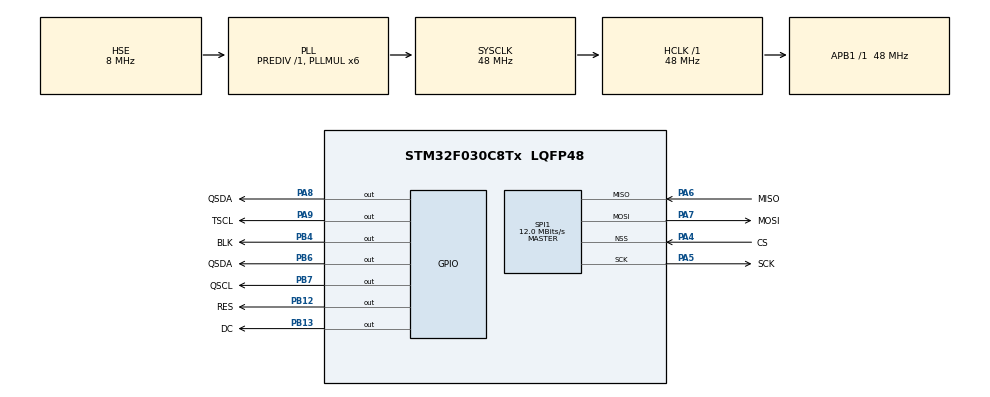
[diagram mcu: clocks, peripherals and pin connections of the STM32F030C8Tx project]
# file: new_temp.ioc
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Mcu.Family=STM32F0
Mcu.Name=STM32F030C8Tx
Mcu.Package=LQFP48
PA0.GPIO_Label=KEY
PA0.Mode=SYS_WakeUp0
PA0.Signal=SYS_WKUP1
PA13.Mode=Serial_Wire
PA13.Signal=SYS_SWDIO
PA14.Mode=Serial_Wire
PA14.Signal=SYS_SWCLK
PA4.GPIO_Label=CS
PA4.Mode=NSS_Signal_Hard_Input
PA4.Signal=SPI1_NSS
PA5.GPIO_Label=SCK
PA5.Mode=Full_Duplex_Master
PA5.Signal=SPI1_SCK
PA6.GPIO_Label=MISO
PA6.Mode=Full_Duplex_Master
PA6.Signal=SPI1_MISO
PA7.GPIO_Label=MOSI
PA7.Mode=Full_Duplex_Master
PA7.Signal=SPI1_MOSI
PA8.GPIO_Label=QSDA
PA8.GPIO_ModeDefaultOutputPP=GPIO_MODE_OUTPUT_OD
PA8.GPIO_PuPd=GPIO_NOPULL
PA8.PinState=GPIO_PIN_SET
PA8.Signal=GPIO_Output
PA9.GPIO_Label=TSCL
PA9.GPIO_ModeDefaultOutputPP=GPIO_MODE_OUTPUT_OD
PA9.GPIO_PuPd=GPIO_NOPULL
PA9.PinState=GPIO_PIN_SET
PA9.Signal=GPIO_Output
PB12.GPIO_Label=RES
PB12.GPIO_ModeDefaultOutputPP=GPIO_MODE_OUTPUT_OD
PB12.GPIO_PuPd=GPIO_NOPULL
PB12.GPIO_Speed=GPIO_SPEED_FREQ_HIGH
PB12.Signal=GPIO_Output
PB13.GPIO_Label=DC
PB13.GPIO_ModeDefaultOutputPP=GPIO_MODE_OUTPUT_OD
PB13.GPIO_PuPd=GPIO_NOPULL
PB13.GPIO_Speed=GPIO_SPEED_FREQ_HIGH
PB13.Signal=GPIO_Output
PB4.GPIO_Label=BLK
PB4.GPIO_ModeDefaultOutputPP=GPIO_MODE_OUTPUT_OD
PB4.GPIO_PuPd=GPIO_NOPULL
PB4.GPIO_Speed=GPIO_SPEED_FREQ_HIGH
PB4.PinState=GPIO_PIN_SET
PB4.Signal=GPIO_Output
PB6.GPIO_Label=QSDA
PB6.PinState=GPIO_PIN_SET
PB6.Signal=GPIO_Output
PB7.GPIO_Label=QSCL
PB7.GPIO_ModeDefaultOutputPP=GPIO_MODE_OUTPUT_OD
PB7.GPIO_PuPd=GPIO_NOPULL
PB7.GPIO_Speed=GPIO_SPEED_FREQ_LOW
PB7.PinState=GPIO_PIN_SET
PB7.Signal=GPIO_Output
PF0-OSC_IN.Mode=HSE-External-Oscillator
PF0-OSC_IN.Signal=RCC_OSC_IN
PF1-OSC_OUT.Mode=HSE-External-Oscillator
PF1-OSC_OUT.Signal=RCC_OSC_OUT
ProjectManager.HeapSize=0x200
ProjectManager.StackSize=0x400
ProjectManager.TargetToolchain=STM32CubeIDE
RCC.AHBFreq_Value=48000000
RCC.APB1Freq_Value=48000000
RCC.APB1TimFreq_Value=48000000
RCC.HCLKFreq_Value=48000000
RCC.PLLMUL=RCC_PLL_MUL6
RCC.PLLSourceVirtual=RCC_PLLSOURCE_HSE
RCC.SYSCLKFreq_VALUE=48000000
RCC.SYSCLKSource=RCC_SYSCLKSOURCE_PLLCLK
SPI1.BaudRatePrescaler=SPI_BAUDRATEPRESCALER_4
SPI1.CRCCalculation=SPI_CRCCALCULATION_DISABLE
SPI1.CalculateBaudRate=12.0 MBits/s
SPI1.DataSize=SPI_DATASIZE_8BIT
SPI1.Direction=SPI_DIRECTION_2LINES
SPI1.Mode=SPI_MODE_MASTER
SPI1.VirtualNSS=VM_NSSHARD
SPI1.VirtualType=VM_MASTER
TIM1.Prescaler=48
VP_TIM1_VS_ClockSourceINT.Mode=Internal
board=custom

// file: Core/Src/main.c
/* USER CODE BEGIN Header */
/**
  ******************************************************************************
  * @file           : main.c
  * @brief          : Main program body
  ******************************************************************************
  * @attention
  *
  * Copyright (c) 2022 STMicroelectronics.
  * All rights reserved.
  *
  * This software is licensed under terms that can be found in the LICENSE file
  * in the root directory of this software component.
  * If no LICENSE file comes with this software, it is provided AS-IS.
  *
  ******************************************************************************
  */
/* USER CODE END Header */
#include "main.h"
#include "lcd_init.h"
#include "lcd.h"

SPI_HandleTypeDef hspi1;

void SystemClock_Config(void);

static void MX_GPIO_Init(void);

static void MX_SPI1_Init(void);

static void MX_TIM1_Init(void);

int main(void) {

    /* MCU Configuration--------------------------------------------------------*/

    /* Reset of all peripherals, Initializes the Flash interface and the Systick. */
    HAL_Init();

    /* Configure the system clock */
    SystemClock_Config();

    /* USER CODE BEGIN SysInit */
    __HAL_RCC_GPIOA_CLK_ENABLE();
    __HAL_RCC_GPIOB_CLK_ENABLE();
    /* USER CODE END SysInit */

    /* Initialize all configured peripherals */
    MX_GPIO_Init();
    MX_SPI1_Init();
    MX_TIM1_Init();
    /* USER CODE BEGIN 2 */
    LCD_GPIO_Init();
    /* USER CODE END 2 */

    /* Infinite loop */
    while (1) {
        LCD_ShowChinese(0,0,"中景园电子",RED,WHITE,24,0);
        LCD_ShowString(24,30,"LCD_W:",RED,WHITE,16,0);
        LCD_ShowIntNum(72,30,LCD_W,3,RED,WHITE,16);
        LCD_ShowString(24,50,"LCD_H:",RED,WHITE,16,0);
        LCD_ShowIntNum(72,50,LCD_H,3,RED,WHITE,16);
//        LCD_ShowFloatNum1(20,80,t,4,RED,WHITE,16);
    }
}

void SystemClock_Config(void) {
    RCC_OscInitTypeDef RCC_OscInitStruct = {0};
    RCC_ClkInitTypeDef RCC_ClkInitStruct = {0};

    /** Initializes the RCC Oscillators according to the specified parameters
    * in the RCC_OscInitTypeDef structure.
    */
    RCC_OscInitStruct.OscillatorType = RCC_OSCILLATORTYPE_HSE;
    RCC_OscInitStruct.HSEState = RCC_HSE_ON;
    RCC_OscInitStruct.PLL.PLLState = RCC_PLL_ON;
    RCC_OscInitStruct.PLL.PLLSource = RCC_PLLSOURCE_HSE;
    RCC_OscInitStruct.PLL.PLLMUL = RCC_PLL_MUL6;
    RCC_OscInitStruct.PLL.PREDIV = RCC_PREDIV_DIV1;
    if (HAL_RCC_OscConfig(&RCC_OscInitStruct) != HAL_OK) {
        Error_Handler();
    }

    /** Initializes the CPU, AHB and APB buses clocks
    */
    RCC_ClkInitStruct.ClockType = RCC_CLOCKTYPE_HCLK | RCC_CLOCKTYPE_SYSCLK
                                  | RCC_CLOCKTYPE_PCLK1;
    RCC_ClkInitStruct.SYSCLKSource = RCC_SYSCLKSOURCE_PLLCLK;
    RCC_ClkInitStruct.AHBCLKDivider = RCC_SYSCLK_DIV1;
    RCC_ClkInitStruct.APB1CLKDivider = RCC_HCLK_DIV1;

    if (HAL_RCC_ClockConfig(&RCC_ClkInitStruct, FLASH_LATENCY_1) != HAL_OK) {
        Error_Handler();
    }
}

static void MX_SPI1_Init(void) {

    /* SPI1 parameter configuration*/
    hspi1.Instance = SPI1;
    hspi1.Init.Mode = SPI_MODE_MASTER;
    hspi1.Init.Direction = SPI_DIRECTION_2LINES;
    hspi1.Init.DataSize = SPI_DATASIZE_8BIT;
    hspi1.Init.CLKPolarity = SPI_POLARITY_LOW;
    hspi1.Init.CLKPhase = SPI_PHASE_1EDGE;
    hspi1.Init.NSS = SPI_NSS_HARD_INPUT;
    hspi1.Init.BaudRatePrescaler = SPI_BAUDRATEPRESCALER_4;
    hspi1.Init.FirstBit = SPI_FIRSTBIT_MSB;
    hspi1.Init.TIMode = SPI_TIMODE_DISABLE;
    hspi1.Init.CRCCalculation = SPI_CRCCALCULATION_DISABLE;
    hspi1.Init.CRCPolynomial = 7;
    hspi1.Init.CRCLength = SPI_CRC_LENGTH_DATASIZE;
    hspi1.Init.NSSPMode = SPI_NSS_PULSE_ENABLE;
    if (HAL_SPI_Init(&hspi1) != HAL_OK) {
        Error_Handler();
    }

}

static void MX_TIM1_Init(void) {

    TIM_ClockConfigTypeDef sClockSourceConfig = {0};
    TIM_MasterConfigTypeDef sMasterConfig = {0};

    htim1.Instance = TIM1;
    htim1.Init.Prescaler = 48;
    htim1.Init.CounterMode = TIM_COUNTERMODE_UP;
    htim1.Init.Period = 65535;
    htim1.Init.ClockDivision = TIM_CLOCKDIVISION_DIV1;
    htim1.Init.RepetitionCounter = 0;
    htim1.Init.AutoReloadPreload = TIM_AUTORELOAD_PRELOAD_DISABLE;
    if (HAL_TIM_Base_Init(&htim1) != HAL_OK) {
        Error_Handler();
    }
    sClockSourceConfig.ClockSource = TIM_CLOCKSOURCE_INTERNAL;
    if (HAL_TIM_ConfigClockSource(&htim1, &sClockSourceConfig) != HAL_OK) {
        Error_Handler();
    }
    sMasterConfig.MasterOutputTrigger = TIM_TRGO_RESET;
    sMasterConfig.MasterSlaveMode = TIM_MASTERSLAVEMODE_DISABLE;
    if (HAL_TIMEx_MasterConfigSynchronization(&htim1, &sMasterConfig) != HAL_OK) {
        Error_Handler();
    }

}

static void MX_GPIO_Init(void) {
    GPIO_InitTypeDef GPIO_InitStruct = {0};

    /* GPIO Ports Clock Enable */
    __HAL_RCC_GPIOC_CLK_ENABLE();
    __HAL_RCC_GPIOF_CLK_ENABLE();
    __HAL_RCC_GPIOA_CLK_ENABLE();
    __HAL_RCC_GPIOB_CLK_ENABLE();

    /*Configure GPIO pin Output Level */
//  HAL_GPIO_WritePin(GPIOB, RES_Pin|DC_Pin, GPIO_PIN_RESET);

    /*Configure GPIO pin Output Level */
//  HAL_GPIO_WritePin(GPIOA, QSDA_Pin|TSCL_Pin, GPIO_PIN_SET);

    /*Configure GPIO pin Output Level */
//  HAL_GPIO_WritePin(GPIOB, BLK_Pin|QSDAB6_Pin|QSCL_Pin, GPIO_PIN_SET);

    /*Configure GPIO pins : PC13 PC14 PC15 */
    GPIO_InitStruct.Pin = GPIO_PIN_13 | GPIO_PIN_14 | GPIO_PIN_15;
    GPIO_InitStruct.Mode = GPIO_MODE_ANALOG;
    GPIO_InitStruct.Pull = GPIO_NOPULL;
    HAL_GPIO_Init(GPIOC, &GPIO_InitStruct);

    /*Configure GPIO pins : PA1 PA2 PA3 PA10
                             PA11 PA12 PA15 */
    GPIO_InitStruct.Pin = GPIO_PIN_1 | GPIO_PIN_2 | GPIO_PIN_3 | GPIO_PIN_10
                          | GPIO_PIN_11 | GPIO_PIN_12 | GPIO_PIN_15;
    GPIO_InitStruct.Mode = GPIO_MODE_ANALOG;
    GPIO_InitStruct.Pull = GPIO_NOPULL;
    HAL_GPIO_Init(GPIOA, &GPIO_InitStruct);

    /*Configure GPIO pins : PB0 PB1 PB2 PB10
                             PB11 PB14 PB15 PB3
                             PB5 PB8 PB9 */
    GPIO_InitStruct.Pin = GPIO_PIN_0 | GPIO_PIN_1 | GPIO_PIN_2 | GPIO_PIN_10
                          | GPIO_PIN_11 | GPIO_PIN_14 | GPIO_PIN_15 | GPIO_PIN_3
                          | GPIO_PIN_5 | GPIO_PIN_8 | GPIO_PIN_9;
    GPIO_InitStruct.Mode = GPIO_MODE_ANALOG;
    GPIO_InitStruct.Pull = GPIO_NOPULL;
    HAL_GPIO_Init(GPIOB, &GPIO_InitStruct);

    /*Configure GPIO pins : RES_Pin DC_Pin BLK_Pin */
//  GPIO_InitStruct.Pin = RES_Pin|DC_Pin|BLK_Pin;
//  GPIO_InitStruct.Mode = GPIO_MODE_OUTPUT_OD;
//  GPIO_InitStruct.Pull = GPIO_NOPULL;
//  GPIO_InitStruct.Speed = GPIO_SPEED_FREQ_HIGH;
//  HAL_GPIO_Init(GPIOB, &GPIO_InitStruct);

    /*Configure GPIO pins : QSDA_Pin TSCL_Pin */
    GPIO_InitStruct.Pin = QSDA_Pin | TSCL_Pin;
    GPIO_InitStruct.Mode = GPIO_MODE_OUTPUT_OD;
    GPIO_InitStruct.Pull = GPIO_NOPULL;
    GPIO_InitStruct.Speed = GPIO_SPEED_FREQ_LOW;
    HAL_GPIO_Init(GPIOA, &GPIO_InitStruct);

    /*Configure GPIO pins : PF6 PF7 */
    GPIO_InitStruct.Pin = GPIO_PIN_6 | GPIO_PIN_7;
    GPIO_InitStruct.Mode = GPIO_MODE_ANALOG;
    GPIO_InitStruct.Pull = GPIO_NOPULL;
    HAL_GPIO_Init(GPIOF, &GPIO_InitStruct);

    /*Configure GPIO pin : QSDAB6_Pin */
    GPIO_InitStruct.Pin = QSDAB6_Pin;
    GPIO_InitStruct.Mode = GPIO_MODE_OUTPUT_PP;
    GPIO_InitStruct.Pull = GPIO_NOPULL;
    GPIO_InitStruct.Speed = GPIO_SPEED_FREQ_LOW;
    HAL_GPIO_Init(QSDAB6_GPIO_Port, &GPIO_InitStruct);

    /*Configure GPIO pin : QSCL_Pin */
    GPIO_InitStruct.Pin = QSCL_Pin;
    GPIO_InitStruct.Mode = GPIO_MODE_OUTPUT_OD;
    GPIO_InitStruct.Pull = GPIO_NOPULL;
    GPIO_InitStruct.Speed = GPIO_SPEED_FREQ_LOW;
    HAL_GPIO_Init(QSCL_GPIO_Port, &GPIO_InitStruct);

}

void Error_Handler(void) {
    __disable_irq();
    while (1) {
    }
}
